# AE1C1F4051920PH0_CM55_HE_View register map
Vendor: Alif Semiconductor; Series: E1; File version: 1.0
CPU: CM55 r1p0, selectable endian, MPU, FPU, double-precision FPU, DSP, VTOR, 8 interrupt priority bits, 1 SAU regions
Registers are 32-bit, read-write, reset 0x0 unless marked. A register's access mark holds for its fields unless they carry their own. Offsets are from the block's base; [hi:lo] are bit positions; lines under a group give offsets from that group; {n}, {i} and the like mark numbered series.

## CDC
Base 0x49031000
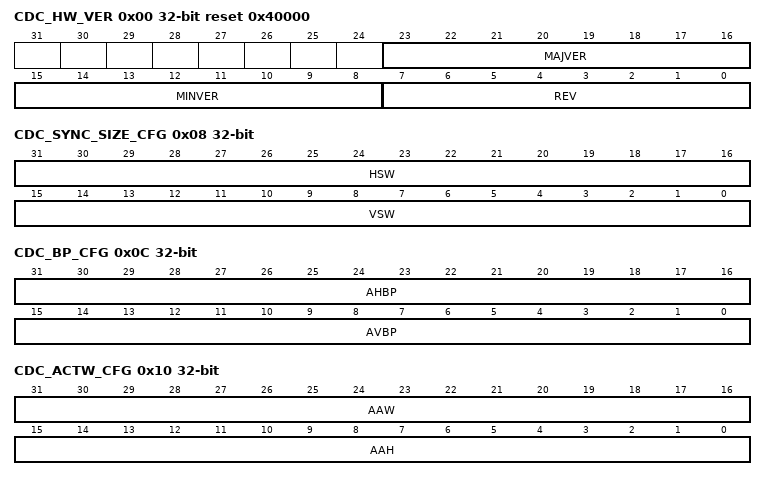
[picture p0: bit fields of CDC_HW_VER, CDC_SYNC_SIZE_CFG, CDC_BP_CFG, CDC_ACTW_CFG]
0x00 CDC_HW_VER ro reset 0x40000 — HW Version Register
  [23:16] MAJVER — Major version.
  [15:8] MINVER — Minor version.
  [7:0] REV — Revision (bug fixes, and others).
0x04 CDC_LCNT ro reset 0x2 — Layer Count Register
  [7:0] LNUM — Number of layers.
0x08 CDC_SYNC_SIZE_CFG — Sync Size Register
  [31:16] HSW — Horizontal sync width - 1 (in units of pixel clock period).
  [15:0] VSW — Vertical sync height - 1 (in units of horizontal scan line).
0x0C CDC_BP_CFG — Back Porch Register
  [31:16] AHBP — Accumulated width including sync and back porch -1 (in units of pixel clock period).
  [15:0] AVBP — Accumulated height including sync and back porch -1 (in units of horizontal scan line).
0x10 CDC_ACTW_CFG — Active Width Register
  [31:16] AAW — Accumulated width including sync, back porch and active width -1 (in units of pixel clock period).
  [15:0] AAH — Accumulated height including sync, back porch and active height -1 (in units of horizontal scan line).
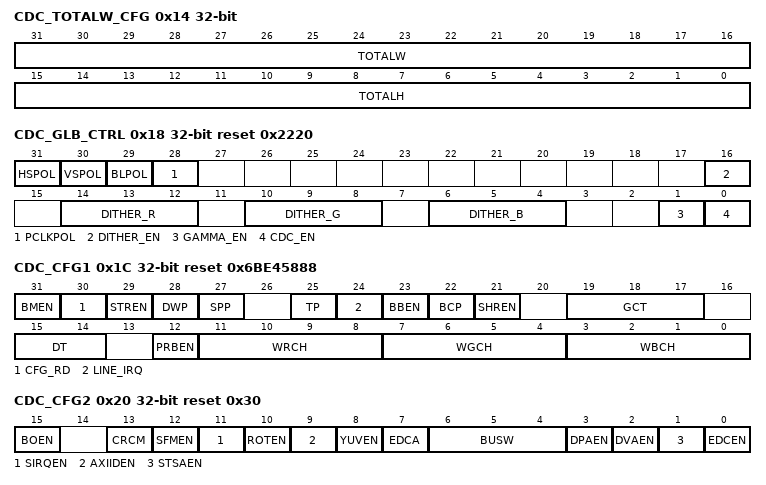
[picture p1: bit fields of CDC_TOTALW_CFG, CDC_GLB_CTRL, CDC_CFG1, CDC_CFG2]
0x14 CDC_TOTALW_CFG — Total Width Register
  [31:16] TOTALW — Total width, including sync, back porch, active width and front porch -1 (in units of pixel clock period).
  [15:0] TOTALH — Total height, including sync, back porch, active height and front porch -1 (in units of horizontal scan line).
0x18 CDC_GLB_CTRL reset 0x2220 — Global Control Register
  [31] HSPOL — HSync polarity. Signal polarity:
    0=Active low; 1=Active high
  [30] VSPOL — VSync polarity. Signal polarity:
    0=Active low; 1=Active high
  [29] BLPOL — Blank polarity. Signal polarity:
    0=Active low; 1=Active high
  [28] PCLKPOL — Output pixel clock polarity. Signal polarity:
    0=Feed-through of PIXEL_CLK input; 1=Inverted PIXEL_CLK input
  [16] DITHER_EN — Dithering on. Dithering can be enabled/disabled. A 4x4 Bayer pattern is added to each color component.
  [14:12] DITHER_R ro — Dither bits red (0-4). Dither bits width for red color component.
  [10:8] DITHER_G ro — Dither bits green (0-4). Dither bits width for green color component.
  [6:4] DITHER_B ro — Dither bits blue (0-4). Dither bits width for blue color component.
  [1] GAMMA_EN — Gamma correction enable. When it is disabled, the RGB data bypasses the gamma correction CLUT.
  [0] CDC_EN — Global enable. Mirrored to pin CDC_DE. The display controller can be globally enabled/disabled. If the display controller is disabled, the timing generator is reset to X = total_width - 1, Y = total_height - 1, and held. Thus only blanking data is output continuously while the display controller is disabled and no new bus accesses are started. Outstanding read data is discarded and the FIFOs are flushed. The value is mirrored to pin CDC_DE.
0x1C CDC_CFG1 ro reset 0x6BE45888 — Global Configuration 1 Register
  [31] BMEN — Blind mode enabled.
  [30] CFG_RD — Configuration reading mode enabled.
  [29] STREN — Status registers enabled.
  [28] DWP — Dither width programmable.
  [27] SPP — Sync polarity programmable.
  [25] TP — Timing programmable.
  [24] LINE_IRQ — Line IRQ position programmable.
  [23] BBEN — Background blending enabled.
  [22] BCP — Background color programmable.
  [21] SHREN — Shadow registers enabled.
  [19:17] GCT — Gamma correction technique.
    0=None; 1=Gamma RAM; 2=Node interpolation
  [15:14] DT — Dithering technique.
    1=Ordered, 4x4 Bayer matrix
  [12] PRBEN — Precise blending enabled.
  [11:8] WRCH — Width of red channel output.
  [7:4] WGCH — Width of green channel output.
  [3:0] WBCH — Width of blue channel output.
0x20 CDC_CFG2 ro reset 0x30 — Global Configuration 2 Register
  [15] BOEN — Blending order enabled.
  [13] CRCM — CRC mode available.
  [12] SFMEN — Single frame ability enabled.
  [11] SIRQEN — Secondary interrupt support enabled.
  [10] ROTEN — Rotation support enabled.
  [9] AXIIDEN — AXI Interface ID support enabled.
  [8] YUVEN — YCbCr output color conversion ability enabled.
  [7] EDCA — External display control ability enabled.
  [6:4] BUSW — Bus width (log2 of number of bytes).
  [3] DPAEN — Secondary RGB output port enabled.
  [2] DVAEN — Dual-view ability enabled.
  [1] STSAEN — Slave timing synchronization ability enabled.
  [0] EDCEN — Background layer ability enabled.
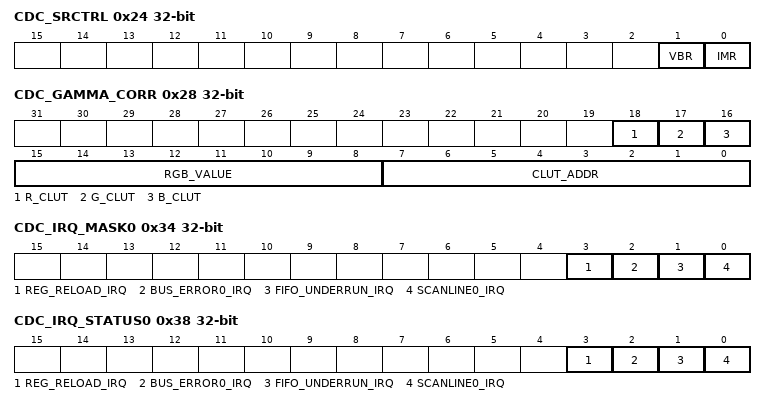
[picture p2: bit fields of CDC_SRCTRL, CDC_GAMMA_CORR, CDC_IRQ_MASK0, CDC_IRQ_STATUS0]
0x24 CDC_SRCTRL — Shadow Reload Control Register
  [1] VBR — Vertical blanking reload (self-clearing after reload, cannot be reset once set).
  [0] IMR — Immediate reload (self-clearing at once).
0x28 CDC_GAMMA_CORR wo reset not defined — Gamma Correction Register
  [18] R_CLUT — Select red CLUT to be written.
  [17] G_CLUT — Select green CLUT to be written.
  [16] B_CLUT — Select blue CLUT to be written.
  [15:8] RGB_VALUE — Mapped color (RGB). Color value to be written to the selected CLUTs.
  [7:0] CLUT_ADDR — Addressed color. Address of CLUT entry to be written.
0x2C CDC_BACKGND_COLOR — Background Color Register
  [23:0] BGC — Background color (RGB). Bits [23-16] define red value. Bits [15-8] define green value. Bits [7-0] define blue value.
0x34 CDC_IRQ_MASK0 — IRQ Enable 1 Register
  [3] REG_RELOAD_IRQ — Register reload IRQ enable.
  [2] BUS_ERROR0_IRQ — Bus error IRQ enable.
  [1] FIFO_UNDERRUN_IRQ — FIFO underrun warning IRQ enable.
  [0] SCANLINE0_IRQ — Line IRQ enable.
0x38 CDC_IRQ_STATUS0 ro — IRQ Status 1 Register
  [3] REG_RELOAD_IRQ — Register reload IRQ status. The Register reload interrupt is generated, if a vertical blanking reload was programmed and the first line after the active area is reached.
  [2] BUS_ERROR0_IRQ — Bus error IRQ status. The Bus error interrupt is generated if an error occurs on the AXI bus.
  [1] FIFO_UNDERRUN_IRQ — FIFO underrun warning IRQ status. The FIFO underrun warning interrupt is generated if one of the layer FIFOs is empty and pixel data is read from the FIFO. This can occur if the color frame buffer length is not defined properly or the master bus performance is too low, such that the pixel data cannot be read in time.
  [0] SCANLINE0_IRQ — Line IRQ status. The Line interrupt is generated when a programmed line number is reached.
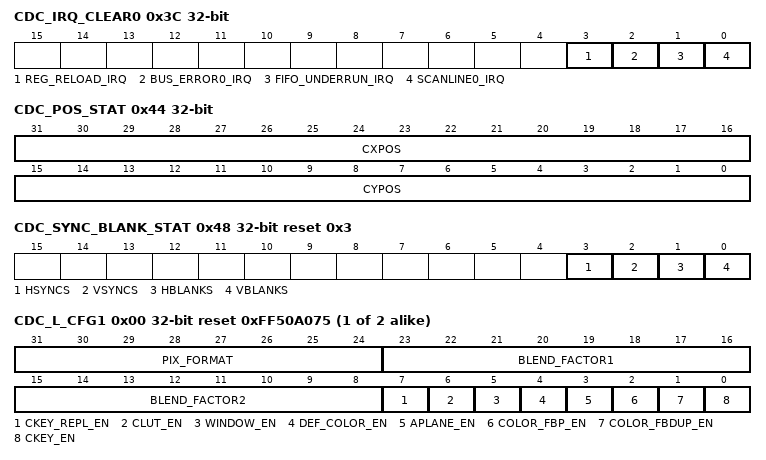
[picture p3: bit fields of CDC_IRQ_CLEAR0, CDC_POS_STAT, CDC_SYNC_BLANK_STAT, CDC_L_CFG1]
0x3C CDC_IRQ_CLEAR0 wo reset not defined — IRQ Clear Register
  [3] REG_RELOAD_IRQ — Clear register reload IRQ.
  [2] BUS_ERROR0_IRQ — Clear bus error IRQ.
  [1] FIFO_UNDERRUN_IRQ — Clear FIFO underrun warning IRQ.
  [0] SCANLINE0_IRQ — Clear line IRQ.
0x40 CDC_LINE_IRQ_POS — Line Number IRQ Control Register
  [15:0] LIPOS — Line IRQ position.
0x44 CDC_POS_STAT ro reset not defined — Position Status Register
  [31:16] CXPOS — This field returns the current X position.
  [15:0] CYPOS — This field returns the current Y position.
0x48 CDC_SYNC_BLANK_STAT ro reset 0x3 — Sync/Blank Status Register
  [all] fields
    0=Active low; 1=Active high
  [3] HSYNCS — HSync (horizontal synchronization) status.
  [2] VSYNCS — VSync (vertical synchronization) status (active high).
  [1] HBLANKS — HBlank (horizontal data enable) status (active high).
  [0] VBLANKS — VBlank (vertical data enable) status (active high).
0x70 CDC_SLINE_IRQ_POS — Secure Line IRQ Position Control Register
  [15:0] SLIPOS — Secure Line IRQ position.
{0x100+0x100*i} CDC_LAYER_CFG[{i}] (i=0..1) group
  0x00 CDC_L_CFG1 ro reset 0xFF50A075 — Layer (n) Configuration 1 Register
    [31:24] PIX_FORMAT — Supported pixel formats (bit mask, custom)
    [23:16] BLEND_FACTOR1 — Supported blending factors for f1: Bit [23]: Reserved Bit [22]: Pixel alpha x constant alpha Bit [21]: Reserved Bit [20]: Constant alpha Bit [19-16]: Reserved
    [15:8] BLEND_FACTOR2 — Supported blending factors for f2: Bit [15]: 1.0 - (pixel alpha x constant alpha) Bit [14]: Reserved Bit [13]: 1.0 - constant alpha Bit [12-8]: Reserved
    [7] CKEY_REPL_EN — Color key replace ability enabled
    [6] CLUT_EN — CLUT ability enabled
    [5] WINDOW_EN — Windowing ability enabled
    [4] DEF_COLOR_EN — Default color programmable
    [3] APLANE_EN — Alpha plane ability enabled
    [2] COLOR_FBP_EN — Color FB pitch ability enabled
    [1] COLOR_FBDUP_EN — Color FB duplication ability enabled
    [0] CKEY_EN — Color key ability enabled
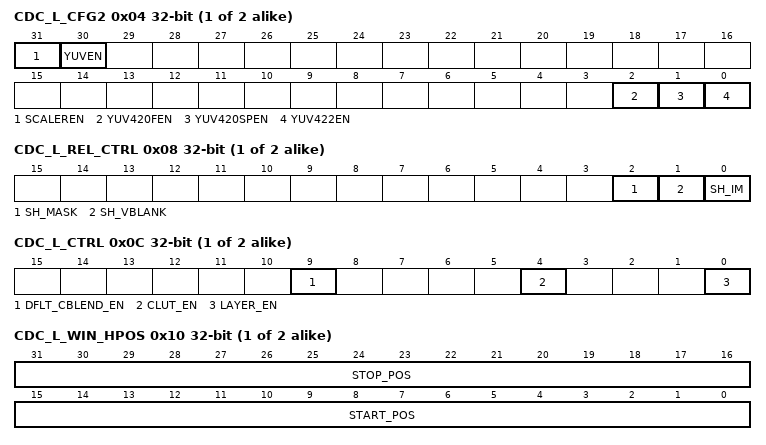
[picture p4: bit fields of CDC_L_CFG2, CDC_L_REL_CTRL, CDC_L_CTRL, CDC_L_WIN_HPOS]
  0x04 CDC_L_CFG2 ro — Layer (n) Configuration 2 Register
    [31] SCALEREN — Scaling ability enabled
    [30] YUVEN — YCbCr ability enabled
    [2] YUV420FEN — YCbCr 4:2:0 fully planar enabled
    [1] YUV420SPEN — YCbCr 4:2:0 semiplanar enabled
    [0] YUV422EN — YCbCr 4:2:2 interleaved enabled
  0x08 CDC_L_REL_CTRL — Layer (n) Shadow Reload Control Register
    [2] SH_MASK — Shadow reload control mask global reloading.
    [1] SH_VBLANK — Shadow reload control vertical blanking.
    [0] SH_IM wo — Shadow reload control immediate.
  0x0C CDC_L_CTRL — Layer (n) Control Register
    [9] DFLT_CBLEND_EN — Default color blending enable. This bit enables blending with the default color for a layer, which is disabled or for pixels on a layer outside of the window. When default color blending is disabled, the color of the subjacent layer is simply passed through for such pixels.
    [4] CLUT_EN — CLUT lookup on. This bit enables/disables the usage of the color look-up table. If enabled, the blue component of the frame buffer pixel after conversion to the internal pixel format is used to look up a RGB value in the table. This RGB value replaces the original RGB value of that pixel. The CLUT is located before the color keying.
    [0] LAYER_EN — Layer on. This bit enables/disables the layer. When a layer is enabled, data is fetched from the frame buffer, that is, the address, number of lines, line length and pitch settings have to be consistent. When a layer is disabled, the default color is used for all pixels.
  0x10 CDC_L_WIN_HPOS — Layer (n) Window Horizontal Position Register
    [31:16] STOP_POS — Horizontal Stop Position.
    [15:0] START_POS — Horizontal Start Position.
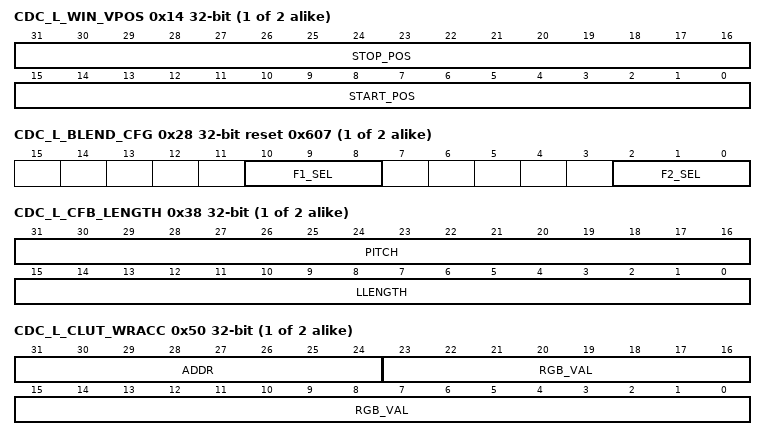
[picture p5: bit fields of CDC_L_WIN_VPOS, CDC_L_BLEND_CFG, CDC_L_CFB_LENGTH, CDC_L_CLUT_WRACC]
  0x14 CDC_L_WIN_VPOS — Layer (n) Window Vertical Position Register
    [31:16] STOP_POS — Vertical Stop Position.
    [15:0] START_POS — Vertical Start Position.
  0x18 CDC_L_CKEY — Layer (n) Color Key Register
    [23:0] TRANS_COLOR — Transparency color.
  0x1C CDC_L_PIX_FORMAT — Layer (n) Pixel Format Register
    [2:0] PIXF — Pixel format selection.
      0=ARGB8888, 32-bit ARGB; 1=RGB888, 24-bit RGB (A = 255); 2=RGB565, 16-bit RGB (A = 255); 3=RGBA8888, 32-bit RGBA; 4=AL44, 8-bit alpha + luminance (lower channel on R, G, and B); 5=A/L8, 8-bit single channel (value on A, R, G, and B); 6=ARGB1555, 16-bit ARGB with 1 bit alpha; 7=ARGB4444, 16-bit ARGB with 4 bits alpha
  0x20 CDC_L_CONST_ALPHA reset 0xFF — Layer (n) Constant Alpha Register
    [7:0] CONSTA — Constant alpha.
  0x24 CDC_L_DFLT_COLOR — Layer (n) Default Color Register
    [31:0] DFLTCOL — Default color (ARGB).
  0x28 CDC_L_BLEND_CFG reset 0x607 — Layer (n) Blending Factors Register
    [10:8] F1_SEL — Selection of blending factor f1. Other values: Reserved
      4=Constant alpha; 6=Pixel alpha x Constant alpha
    [2:0] F2_SEL — Selection of blending factor f2. Other values: Reserved
      5=1 - Constant alpha; 7=Pixel alpha x Constant alpha
  0x2C CDC_L_FB_BCTRL — Layer (n) FB Bus Control Register
    [7:0] WNUM — Number of words per burst when reading the frame buffers.
      0=Maximum burst length (16 words); {v}=1 to 15 words per burst (v=1..15)
  0x34 CDC_L_CFB_ADDR — Layer (n) Color FB Address Register
    [31:0] SADDR — Color FB start address.
  0x38 CDC_L_CFB_LENGTH — Layer (n) Color FB Length Register
    [31:16] PITCH — Pitch of color FB in bytes (signed). The pitch is the increment from the start of one line of pixels to the start of the next line in bytes. It is a signed value. Providing negative values allows a vertical flip of the frame buffer. When reading this register, the sign bit [30] is expanded until bit [31].
    [15:0] LLENGTH — Line length of color FB in bytes - 1 + (width of bus in bytes). The line length is the length of one pixel line in bytes + 7. The value of 7 relates to the bus width (8 bytes in this configuration) and serves to correctly calculate the address of the last word of data for that line internally.
  0x3C CDC_L_CFB_LINES — Layer (n) Color FB Lines Register
    [15:0] LNUM — Number of lines in the color FB.
  0x50 CDC_L_CLUT_WRACC wo reset not defined — Layer (n) CLUT Write Access Register
    [31:24] ADDR — Address of CLUT entry.
    [23:0] RGB_VAL — RGB888 value to be written.
